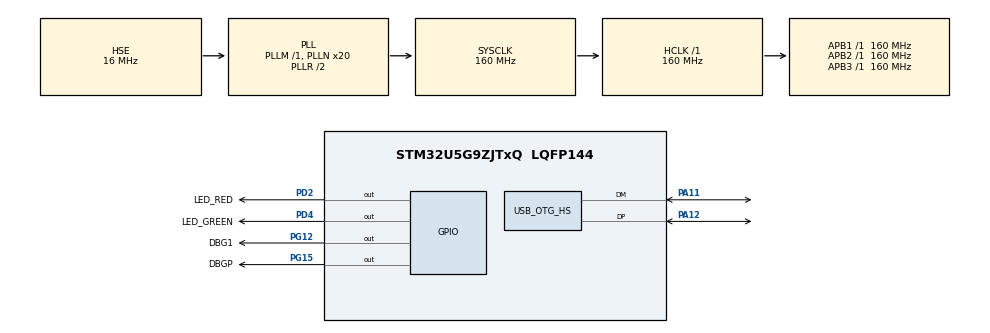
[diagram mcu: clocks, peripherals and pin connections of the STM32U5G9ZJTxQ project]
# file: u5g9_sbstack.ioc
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CORTEX_M33_NS.userName=CORTEX_M33
Mcu.Family=STM32U5
Mcu.Name=STM32U5G9ZJTxQ
Mcu.Package=LQFP144
NVIC.OTG_HS_IRQn=true\:7\:0\:true\:false\:true\:true\:true\:true
NVIC.PriorityGroup=NVIC_PRIORITYGROUP_4
NVIC.TIM6_IRQn=true\:15\:0\:false\:false\:true\:false\:true\:true
NVIC.TimeBase=TIM6_IRQn
NVIC.TimeBaseIP=TIM6
PA11.GPIO_Speed=GPIO_SPEED_FREQ_LOW
PA11.Mode=Internal_Phy_Device
PA11.Signal=USB_OTG_HS_DM
PA12.GPIO_Speed=GPIO_SPEED_FREQ_LOW
PA12.Mode=Internal_Phy_Device
PA12.Signal=USB_OTG_HS_DP
PA13\ (JTMS/SWDIO).Mode=Serial_Wire
PA13\ (JTMS/SWDIO).Signal=DEBUG_JTMS-SWDIO
PA14\ (JTCK/SWCLK).Mode=Serial_Wire
PA14\ (JTCK/SWCLK).Signal=DEBUG_JTCK-SWCLK
PD2.GPIO_Label=LED_RED
PD2.GPIO_Speed=GPIO_SPEED_FREQ_HIGH
PD2.PinState=GPIO_PIN_SET
PD2.Signal=GPIO_Output
PD4.GPIO_Label=LED_GREEN
PD4.PinState=GPIO_PIN_SET
PD4.Signal=GPIO_Output
PG12.GPIO_Label=DBG1
PG12.Signal=GPIO_Output
PG15.GPIO_Label=DBGP
PG15.Signal=GPIO_Output
PH0-OSC_IN\ (PH0).Mode=HSE-External-Oscillator
PH0-OSC_IN\ (PH0).Signal=RCC_OSC_IN
PH1-OSC_OUT\ (PH1).Mode=HSE-External-Oscillator
PH1-OSC_OUT\ (PH1).Signal=RCC_OSC_OUT
ProjectManager.HeapSize=0x200
ProjectManager.StackSize=0x400
ProjectManager.TargetToolchain=STM32CubeIDE
RCC.ADCFreq_Value=16000000
RCC.AHBFreq_Value=160000000
RCC.APB1Freq_Value=160000000
RCC.APB1TimFreq_Value=160000000
RCC.APB2Freq_Value=160000000
RCC.APB2TimFreq_Value=160000000
RCC.APB3Freq_Value=160000000
RCC.CortexFreq_Value=160000000
RCC.DACCLockSelectionVirtual=RCC_DAC1CLKSOURCE_LSI
RCC.EPOD_VALUE=16000000
RCC.HCLKFreq_Value=160000000
RCC.HSE_VALUE=16000000
RCC.HSI48_VALUE=48000000
RCC.HSI_VALUE=16000000
RCC.LSE_VALUE=32768
RCC.LSIDIV_VALUE=32000
RCC.MSIClockRange=RCC_MSIRANGE_0
RCC.MSI_VALUE=48000000
RCC.PLL1P=8
RCC.PLL2FRACN=0
RCC.PLL3FRACN=0
RCC.PLLFRACN=0
RCC.PLLN=20
RCC.PLLSourceVirtual=RCC_PLLSOURCE_HSE
RCC.SYSCLKFreq_VALUE=160000000
RCC.SYSCLKSource=RCC_SYSCLKSOURCE_PLLCLK
RCC.USBPHYCLockSelection=RCC_USBPHYCLKSOURCE_HSE
RCC.VCOOutputFreq_Value=320000000
USB_OTG_HS.DeviceSpeed=PCD_SPEED_HIGH
USB_OTG_HS.VirtualMode=Device_HS
VP_ICACHE_VS_ICACHE.Mode=DirectMappedCache
VP_LPBAMQUEUE_VS_QUEUE.Mode=QUEUEMODE
VP_LPBAM_VS_SIG1.Mode=SmartRun
VP_LPBAM_VS_SIG4.Mode=LPDMA1
VP_MEMORYMAP_VS_MEMORYMAP.Mode=CurAppReg
VP_PWR_VS_SECSignals.Mode=Security/Privilege
VP_SYS_VS_tim6.Mode=TIM6
board=STM32U5G9J-DK2

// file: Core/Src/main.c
/* USER CODE BEGIN Header */
/**
 ******************************************************************************
 * @file           : main.c
 * @brief          : Main program body
 ******************************************************************************
 * @attention
 *
 * Copyright (c) 2025 STMicroelectronics.
 * All rights reserved.
 *
 * This software is licensed under terms that can be found in the LICENSE file
 * in the root directory of this software component.
 * If no LICENSE file comes with this software, it is provided AS-IS.
 *
 ******************************************************************************
 */
/* USER CODE END Header */
#include "main.h"

/* USER CODE BEGIN Includes */

#include "usb_device.h"

/* USER CODE END Includes */

/* USER CODE BEGIN PD */

#define PACKET_SIZE 256
#define FILL_VALUE 85

/* USER CODE END PD */

PCD_HandleTypeDef hpcd_USB_OTG_HS;

/* USER CODE BEGIN PV */

uint8_t buffer[PACKET_SIZE];

/* USER CODE END PV */

void SystemClock_Config(void);
static void MX_GPIO_Init(void);
static void MX_ICACHE_Init(void);
/* USER CODE BEGIN PFP */

void Fill_Buffer(void) {
    memset(buffer, FILL_VALUE, PACKET_SIZE);
}

/* USER CODE END PFP */

int main(void)
{

  /* MCU Configuration--------------------------------------------------------*/

  /* Reset of all peripherals, Initializes the Flash interface and the Systick. */
  HAL_Init();

  /* Configure the system clock */
  SystemClock_Config();

  /* Initialize all configured peripherals */
  MX_GPIO_Init();
  MX_ICACHE_Init();
  /* USER CODE BEGIN 2 */
  MX_USB_OTG_HS_PCD_Init();
	MX_USB_DEVICE_Init();

	Fill_Buffer();
  /* USER CODE END 2 */

  /* Infinite loop */
  /* USER CODE BEGIN WHILE */
	uint8_t msg[] = "Hello, USB CDC!\r\n";

	while (1) {
    /* USER CODE END WHILE */

    /* USER CODE BEGIN 3 */

		//CDC_Transmit_HS(msg, sizeof(msg) - 1);
		CDC_Transmit_HS(buffer, PACKET_SIZE);
		//HAL_Delay(1000);

		//to receive - edit CDC_Receive_HS() function at usbd_cdc_if.c file

	}
  /* USER CODE END 3 */
}

void SystemClock_Config(void)
{
  RCC_OscInitTypeDef RCC_OscInitStruct = {0};
  RCC_ClkInitTypeDef RCC_ClkInitStruct = {0};

  /** Configure the main internal regulator output voltage
  */
  if (HAL_PWREx_ControlVoltageScaling(PWR_REGULATOR_VOLTAGE_SCALE1) != HAL_OK)
  {
    Error_Handler();
  }

  /** Initializes the CPU, AHB and APB buses clocks
  */
  RCC_OscInitStruct.OscillatorType = RCC_OSCILLATORTYPE_HSE;
  RCC_OscInitStruct.HSEState = RCC_HSE_ON;
  RCC_OscInitStruct.PLL.PLLState = RCC_PLL_ON;
  RCC_OscInitStruct.PLL.PLLSource = RCC_PLLSOURCE_HSE;
  RCC_OscInitStruct.PLL.PLLMBOOST = RCC_PLLMBOOST_DIV1;
  RCC_OscInitStruct.PLL.PLLM = 1;
  RCC_OscInitStruct.PLL.PLLN = 20;
  RCC_OscInitStruct.PLL.PLLP = 8;
  RCC_OscInitStruct.PLL.PLLQ = 2;
  RCC_OscInitStruct.PLL.PLLR = 2;
  RCC_OscInitStruct.PLL.PLLRGE = RCC_PLLVCIRANGE_1;
  RCC_OscInitStruct.PLL.PLLFRACN = 0;
  if (HAL_RCC_OscConfig(&RCC_OscInitStruct) != HAL_OK)
  {
    Error_Handler();
  }

  /** Initializes the CPU, AHB and APB buses clocks
  */
  RCC_ClkInitStruct.ClockType = RCC_CLOCKTYPE_HCLK|RCC_CLOCKTYPE_SYSCLK
                              |RCC_CLOCKTYPE_PCLK1|RCC_CLOCKTYPE_PCLK2
                              |RCC_CLOCKTYPE_PCLK3;
  RCC_ClkInitStruct.SYSCLKSource = RCC_SYSCLKSOURCE_PLLCLK;
  RCC_ClkInitStruct.AHBCLKDivider = RCC_SYSCLK_DIV1;
  RCC_ClkInitStruct.APB1CLKDivider = RCC_HCLK_DIV1;
  RCC_ClkInitStruct.APB2CLKDivider = RCC_HCLK_DIV1;
  RCC_ClkInitStruct.APB3CLKDivider = RCC_HCLK_DIV1;

  if (HAL_RCC_ClockConfig(&RCC_ClkInitStruct, FLASH_LATENCY_4) != HAL_OK)
  {
    Error_Handler();
  }
}

static void MX_ICACHE_Init(void)
{

  /** Enable instruction cache in 1-way (direct mapped cache)
  */
  if (HAL_ICACHE_ConfigAssociativityMode(ICACHE_1WAY) != HAL_OK)
  {
    Error_Handler();
  }
  if (HAL_ICACHE_Enable() != HAL_OK)
  {
    Error_Handler();
  }

}

void MX_USB_OTG_HS_PCD_Init(void)
{

  hpcd_USB_OTG_HS.Instance = USB_OTG_HS;
  hpcd_USB_OTG_HS.Init.dev_endpoints = 9;
  hpcd_USB_OTG_HS.Init.speed = PCD_SPEED_HIGH;
  hpcd_USB_OTG_HS.Init.phy_itface = USB_OTG_HS_EMBEDDED_PHY;
  hpcd_USB_OTG_HS.Init.Sof_enable = DISABLE;
  hpcd_USB_OTG_HS.Init.low_power_enable = DISABLE;
  hpcd_USB_OTG_HS.Init.lpm_enable = DISABLE;
  hpcd_USB_OTG_HS.Init.use_dedicated_ep1 = DISABLE;
  hpcd_USB_OTG_HS.Init.vbus_sensing_enable = DISABLE;
  hpcd_USB_OTG_HS.Init.dma_enable = DISABLE;
  if (HAL_PCD_Init(&hpcd_USB_OTG_HS) != HAL_OK)
  {
    Error_Handler();
  }

}

static void MX_GPIO_Init(void)
{
  GPIO_InitTypeDef GPIO_InitStruct = {0};

  /* GPIO Ports Clock Enable */
  __HAL_RCC_GPIOH_CLK_ENABLE();
  __HAL_RCC_GPIOA_CLK_ENABLE();
  __HAL_RCC_GPIOD_CLK_ENABLE();
  __HAL_RCC_GPIOG_CLK_ENABLE();

  /*Configure GPIO pin Output Level */
  HAL_GPIO_WritePin(GPIOD, LED_RED_Pin|LED_GREEN_Pin, GPIO_PIN_SET);

  /*Configure GPIO pin Output Level */
  HAL_GPIO_WritePin(GPIOG, DBG1_Pin|DBGP_Pin, GPIO_PIN_RESET);

  /*Configure GPIO pin : LED_RED_Pin */
  GPIO_InitStruct.Pin = LED_RED_Pin;
  GPIO_InitStruct.Mode = GPIO_MODE_OUTPUT_PP;
  GPIO_InitStruct.Pull = GPIO_NOPULL;
  GPIO_InitStruct.Speed = GPIO_SPEED_FREQ_HIGH;
  HAL_GPIO_Init(LED_RED_GPIO_Port, &GPIO_InitStruct);

  /*Configure GPIO pin : LED_GREEN_Pin */
  GPIO_InitStruct.Pin = LED_GREEN_Pin;
  GPIO_InitStruct.Mode = GPIO_MODE_OUTPUT_PP;
  GPIO_InitStruct.Pull = GPIO_NOPULL;
  GPIO_InitStruct.Speed = GPIO_SPEED_FREQ_LOW;
  HAL_GPIO_Init(LED_GREEN_GPIO_Port, &GPIO_InitStruct);

  /*Configure GPIO pins : DBG1_Pin DBGP_Pin */
  GPIO_InitStruct.Pin = DBG1_Pin|DBGP_Pin;
  GPIO_InitStruct.Mode = GPIO_MODE_OUTPUT_PP;
  GPIO_InitStruct.Pull = GPIO_NOPULL;
  GPIO_InitStruct.Speed = GPIO_SPEED_FREQ_LOW;
  HAL_GPIO_Init(GPIOG, &GPIO_InitStruct);

}

void HAL_TIM_PeriodElapsedCallback(TIM_HandleTypeDef *htim)
{
  if (htim->Instance == TIM6) {
    HAL_IncTick();
  }
}

void Error_Handler(void)
{
	__disable_irq();
	while (1) {
	}
}
